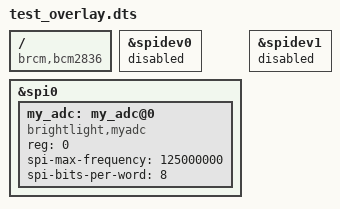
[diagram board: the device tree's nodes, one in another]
/dts-v1/;
/plugin/;
/ {
	compatible = "brcm,bcm2836";
	fragment@0 {
		target = <&spidev0>;
		__overlay__ {
			status = "disabled";
		};
	};
		
	fragment@1 {
		target = <&spi0>;
		__overlay__ {
			#address-cells = <1>;
			#size-cells = <0>;

			my_adc: my_adc@0 {
				status = "okay";
				compatible = "brightlight,myadc";
				reg = <0>;
				spi-max-frequency = <125000000>;
				spi-bits-per-word = <8>;
			};
		};
	}; 

		fragment@2 {
		target = <&spidev1>;
		__overlay__ {
			status = "disabled";
		};
	};
};
